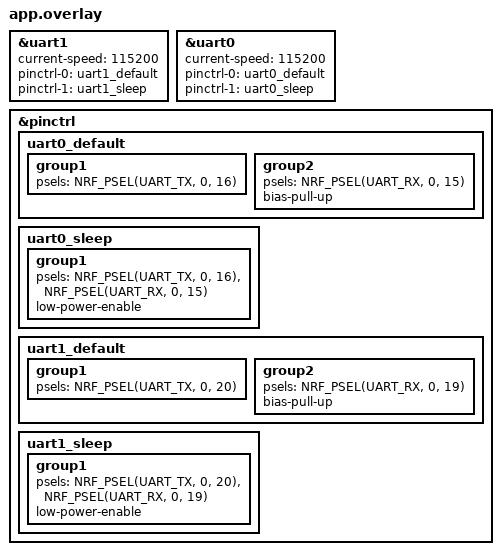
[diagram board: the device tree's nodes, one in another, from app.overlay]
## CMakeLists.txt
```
cmake_minimum_required(VERSION 3.20.0)
find_package(Zephyr REQUIRED HINTS $ENV{ZEPHYR_BASE})
project(first)

target_sources(app PRIVATE src/main.c)
```

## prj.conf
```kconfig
CONFIG_SERIAL=y
CONFIG_UART_INTERRUPT_DRIVEN=y
CONFIG_PRINTK=y
```

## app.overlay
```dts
/* UART1: TX P0.20, RX P0.19 */
&uart1 {
    status = "okay";
    current-speed = <115200>;
    pinctrl-0 = <&uart1_default>;
    pinctrl-1 = <&uart1_sleep>;
    pinctrl-names = "default", "sleep";
};

/* UART0 as UART2: TX P0.16, RX P0.15 */
&uart0 {
    status = "okay";
    current-speed = <115200>;
    pinctrl-0 = <&uart0_default>;
    pinctrl-1 = <&uart0_sleep>;
    pinctrl-names = "default", "sleep";
};

&pinctrl {
    uart0_default: uart0_default {
        group1 {
            psels = <NRF_PSEL(UART_TX, 0, 16)>;
        };
        group2 {
            psels = <NRF_PSEL(UART_RX, 0, 15)>;
            bias-pull-up;
        };
    };

    uart0_sleep: uart0_sleep {
        group1 {
            psels = <NRF_PSEL(UART_TX, 0, 16)>,
                    <NRF_PSEL(UART_RX, 0, 15)>;
            low-power-enable;
        };
    };

    uart1_default: uart1_default {
        group1 {
            psels = <NRF_PSEL(UART_TX, 0, 20)>;
        };
        group2 {
            psels = <NRF_PSEL(UART_RX, 0, 19)>;
            bias-pull-up;
        };
    };

    uart1_sleep: uart1_sleep {
        group1 {
            psels = <NRF_PSEL(UART_TX, 0, 20)>,
                    <NRF_PSEL(UART_RX, 0, 19)>;
            low-power-enable;
        };
    };
};
```

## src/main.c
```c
#include <zephyr/kernel.h>
#include <zephyr/device.h>
#include <zephyr/drivers/uart.h>
#include <string.h>
#include <stdio.h>

/* UART2: TX P0.16, RX P0.15 -> mapped to uart0 */
static const struct device *uart2_dev = DEVICE_DT_GET(DT_NODELABEL(uart0));

/* UART1: TX P0.20, RX P0.19 -> mapped to uart1 */
static const struct device *uart1_dev = DEVICE_DT_GET(DT_NODELABEL(uart1));

static void uart_send_string(const struct device *dev, const char *str)
{
    while (*str) {
        uart_poll_out(dev, *str++);
    }
}

int main(void)
{
    uint32_t counter = 0;
    char buf[64];

    if (!device_is_ready(uart2_dev)) {
        return -1;
    }

    if (!device_is_ready(uart1_dev)) {
        return -1;
    }

    while (1) {
        snprintf(buf, sizeof(buf), "UART2 count: %u\r\n", counter);
        uart_send_string(uart2_dev, buf);

        snprintf(buf, sizeof(buf), "UART1 count: %u\r\n", counter);
        uart_send_string(uart1_dev, buf);

        counter++;
        k_sleep(K_SECONDS(1));
    }

    return 0;
}
```
